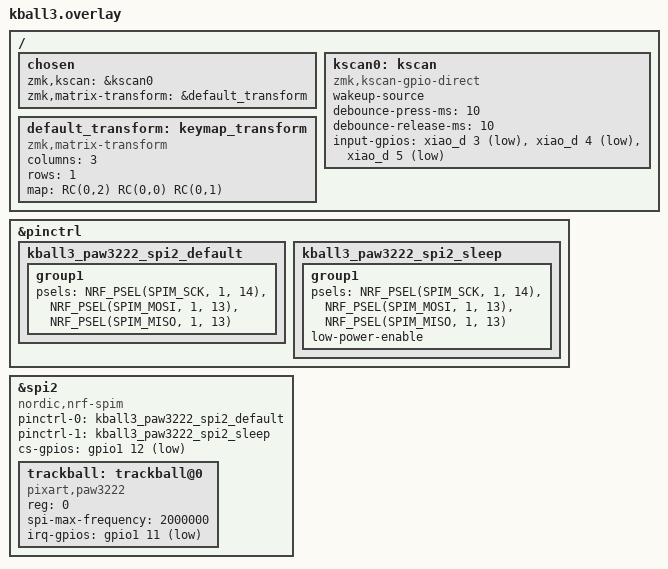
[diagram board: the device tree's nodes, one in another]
#include <dt-bindings/zmk/matrix_transform.h>

/ {
    chosen {
        zmk,kscan = &kscan0;
        zmk,matrix-transform = &default_transform;
    };

    kscan0: kscan {
        compatible = "zmk,kscan-gpio-direct";
        wakeup-source;
        debounce-press-ms = <10>;
        debounce-release-ms = <10>;

        input-gpios
            = <&xiao_d 3 (GPIO_ACTIVE_LOW | GPIO_PULL_UP)>  /* BTN1 */
            , <&xiao_d 4 (GPIO_ACTIVE_LOW | GPIO_PULL_UP)>  /* BTN2 */
            , <&xiao_d 5 (GPIO_ACTIVE_LOW | GPIO_PULL_UP)>  /* BTN3 */
            ;
    };

    default_transform: keymap_transform {
        compatible = "zmk,matrix-transform";
        columns = <3>;
        rows = <1>;
        map = <
            RC(0,2)
            RC(0,0)
            RC(0,1)
        >;
    };
};

&pinctrl {
    kball3_paw3222_spi2_default: kball3_paw3222_spi2_default {
        group1 {
            psels = <NRF_PSEL(SPIM_SCK, 1, 14)>,  /* XIAO D9: SCLK */
                    <NRF_PSEL(SPIM_MOSI, 1, 13)>, /* XIAO D8: SDIO */
                    <NRF_PSEL(SPIM_MISO, 1, 13)>; /* XIAO D8: SDIO */
        };
    };

    kball3_paw3222_spi2_sleep: kball3_paw3222_spi2_sleep {
        group1 {
            psels = <NRF_PSEL(SPIM_SCK, 1, 14)>,
                    <NRF_PSEL(SPIM_MOSI, 1, 13)>,
                    <NRF_PSEL(SPIM_MISO, 1, 13)>;
            low-power-enable;
        };
    };
};

&spi2 {
    status = "okay";
    compatible = "nordic,nrf-spim";
    pinctrl-0 = <&kball3_paw3222_spi2_default>;
    pinctrl-1 = <&kball3_paw3222_spi2_sleep>;
    pinctrl-names = "default", "sleep";
    cs-gpios = <&gpio1 12 GPIO_ACTIVE_LOW>; /* XIAO D7: CS */

    trackball: trackball@0 {
        status = "okay";
        compatible = "pixart,paw3222";
        reg = <0>;
        spi-max-frequency = <2000000>;
        irq-gpios = <&gpio1 11 GPIO_ACTIVE_LOW>; /* XIAO D6: MOTION */
    };
};
